VERSION ""

NS_ :

BS_:

BU_: Device Host

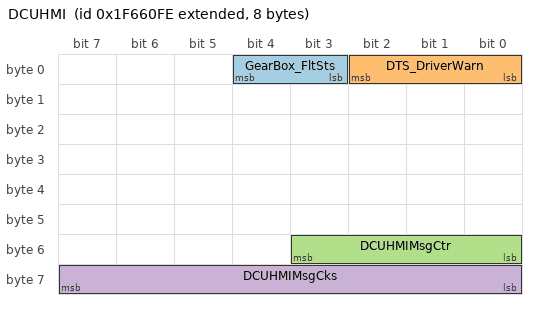
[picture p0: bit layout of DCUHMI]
BO_ 2180407550 DCUHMI: 8 Vector__XXX
 SG_ GearBox_FltSts : 3|2@1+ (1,0) [0|3] "" Vector__XXX
 SG_ DTS_DriverWarn : 0|3@1+ (1,0) [0|7] "" Vector__XXX
 SG_ DCUHMIMsgCtr : 48|4@1+ (1,0) [0|15] "" Vector__XXX
 SG_ DCUHMIMsgCks : 56|8@1+ (1,0) [0|255] "" Vector__XXX

CM_ "Arrival Bus Drivetrain System Database";
CM_ SG_ 2180407550 DCUHMIMsgCtr "Message counter to verify the signal path from the demanding device to the controller";
CM_ SG_ 2180407550 DCUHMIMsgCks "Message checksum to verify the signal path from the demanding device to the controller.
Calculated according to AUTOSAR profile 1A";
BA_DEF_  "BusType" STRING ;
BA_DEF_  "DBName" STRING ;
BA_DEF_  "DatabaseVersion" STRING ;
BA_DEF_ BO_  "GenMsgCycleTime" INT 0 3600000;
BA_DEF_ BO_  "GenMsgILSupport" ENUM  "No","Yes";
BA_DEF_ BO_  "GenMsgRequestable" INT 0 1;
BA_DEF_ BO_  "GenMsgSendType" ENUM  "cyclic","NotUsed","NotUsed","NotUsed","NotUsed","NotUsed","NotUsed","IfActive","noMsgSendType";
BA_DEF_ SG_  "GenSigEVName" STRING ;
BA_DEF_ SG_  "GenSigILSupport" ENUM  "No","Yes";
BA_DEF_ SG_  "GenSigSendType" ENUM  "Cyclic","OnWrite","OnWriteWithRepetition","OnChange","OnChangeWithRepetition","IfActive","IfActiveWithRepetition","NoSigSendType";
BA_DEF_ SG_  "GenSigStartValue" INT 0 2147483647;
BA_DEF_ BU_  "NmStationAddress" INT 0 255;
BA_DEF_  "ProtocolType" STRING ;
BA_DEF_  "SAE_J1939_21_SpecVersion" STRING ;
BA_DEF_  "SAE_J1939_71_SpecVersion" STRING ;
BA_DEF_  "SAE_J1939_73_SpecVersion" STRING ;
BA_DEF_  "SAE_J1939_75_SpecVersion" STRING ;
BA_DEF_  "SAE_J1939_81_SpecVersion" STRING ;
BA_DEF_  "SAE_J1939_DA_SpecVersion" STRING ;
BA_DEF_ BO_  "Producer" STRING ;
BA_DEF_ SG_  "SigType" ENUM  "Default","Range","RangeSigned","ASCII","Discrete","Control","ReferencePGN","DTC","StringDelimiter","StringLength","StringLengthControl","MessageCounter","MessageChecksum";
BA_DEF_ BO_  "VFrameFormat" ENUM  "StandardCAN","ExtendedCAN","reserved","J1939PG","reserved","reserved","reserved","reserved","reserved","reserved","reserved","reserved","reserved","reserved","StandardCAN_FD","ExtendedCAN_FD";
BA_DEF_DEF_  "BusType" "";
BA_DEF_DEF_ "Producer" "DTS" ;
BA_DEF_DEF_  "DBName" "";
BA_DEF_DEF_  "DatabaseVersion" "";
BA_DEF_DEF_  "GenMsgCycleTime" 0;
BA_DEF_DEF_  "GenMsgILSupport" "Yes";
BA_DEF_DEF_  "GenMsgRequestable" 1;
BA_DEF_DEF_  "GenMsgSendType" "noMsgSendType";
BA_DEF_DEF_  "GenSigEVName" "Env@Nodename_@Signame";
BA_DEF_DEF_  "GenSigILSupport" "Yes";
BA_DEF_DEF_  "GenSigSendType" "NoSigSendType";
BA_DEF_DEF_  "GenSigStartValue" 0;
BA_DEF_DEF_  "NmStationAddress" 254;
BA_DEF_DEF_  "ProtocolType" "";
BA_DEF_DEF_  "SAE_J1939_21_SpecVersion" "";
BA_DEF_DEF_  "SAE_J1939_71_SpecVersion" "";
BA_DEF_DEF_  "SAE_J1939_73_SpecVersion" "";
BA_DEF_DEF_  "SAE_J1939_75_SpecVersion" "";
BA_DEF_DEF_  "SAE_J1939_81_SpecVersion" "";
BA_DEF_DEF_  "SAE_J1939_DA_SpecVersion" "";
BA_DEF_DEF_  "SigType" "Default";
BA_DEF_DEF_  "VFrameFormat" "J1939PG";
BA_ "BusType" "CAN";
BA_ "DatabaseVersion" "1.0";
BA_ "ProtocolType" "J1939";
BA_ "SAE_J1939_21_SpecVersion" "2006-10";
BA_ "SAE_J1939_71_SpecVersion" "2012-10";
BA_ "SAE_J1939_73_SpecVersion" "2012-10";
BA_ "SAE_J1939_75_SpecVersion" "2012-05";
BA_ "SAE_J1939_81_SpecVersion" "2012-05";
BA_ "SAE_J1939_DA_SpecVersion" "2015-01";
BA_ "DBName" "DrivetrainSystem";
BA_ "GenMsgCycleTime" BO_ 2180407550 500;
BA_ "GenMsgSendType" BO_ 2180407550 0;
BA_ "SigType" SG_ 2180407550 GearBox_FltSts 4;
BA_ "SigType" SG_ 2180407550 DTS_DriverWarn 4;
BA_ "SigType" SG_ 2180407550 DCUHMIMsgCtr 11;
BA_ "SigType" SG_ 2180407550 DCUHMIMsgCks 12;
VAL_ 2180407550 GearBox_FltSts 3 "NA_GBFltSts" 2 "CriticalGBFaultSts" 1 "MinorGBFaultSts" 0 "NoGBFaultSts" ;
VAL_ 2180407550 DTS_DriverWarn 7 "NA_DrvrWarn" 4 "CriticalDrivetrainFault_Latched" 3 "CriticalDrivetrainFault" 2 "MajorDrivetrainFault" 1 "MinorDrivetrainFault" 0 "NoDrivetrainFault" ;
